# GD32E51x_HD register map
File version: 1.0
CPU: CM33 r0p4, little endian, MPU, FPU, 4 interrupt priority bits
Registers are 32-bit, read-write, reset 0x0 unless marked. A register's access mark holds for its fields unless they carry their own. Offsets are from the block's base; [hi:lo] are bit positions; {n}, {i} and the like mark numbered series.

## BKP — Backup registers
Base 0x40006C00
{0x4+4i} DATA{i} 16-bit (i=0..9) — Backup data register {i}
  [15:0] DATA — Backup data
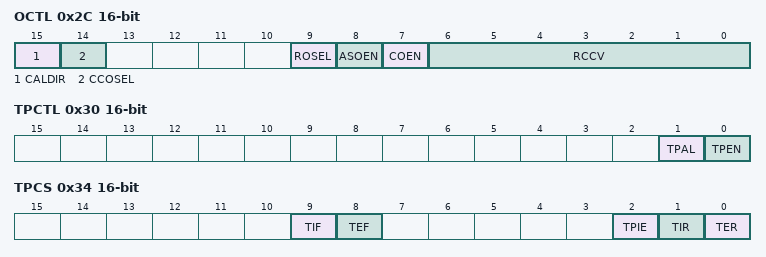
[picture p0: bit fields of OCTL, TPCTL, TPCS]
0x2C OCTL 16-bit — RTC signal output control register
  [15] CALDIR — RTC clock calibration direction
  [14] CCOSEL — RTC clock output selection
  [9] ROSEL — RTC output selection
  [8] ASOEN — RTC alarm or second signal output enable
  [7] COEN — RTC clock calibration output enable
  [6:0] RCCV — RTC clock calibration value
0x30 TPCTL 16-bit — Tamper pin control register
  [1] TPAL — TAMPER pin active level
  [0] TPEN — TAMPER detection enable
0x34 TPCS 16-bit — Tamper control and status register
  [9] TIF — Tamper interrupt flag
  [8] TEF — Tamper event flag
  [2] TPIE — Tamper interrupt enable
  [1] TIR — Tamper interrupt reset
  [0] TER — Tamper event reset
{0x18+4i} DATA{i} 16-bit (i=10..41) — Backup data register {i}
  [15:0] DATA — Backup data

## CMP — Comparator
Base 0x40017C00
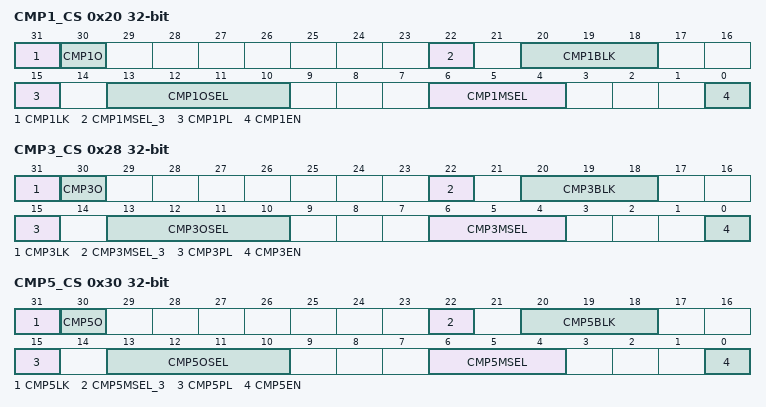
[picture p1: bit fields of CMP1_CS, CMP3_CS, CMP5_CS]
0x20 CMP1_CS access per field — CMP1 control and status register
  [31] CMP1LK rw — Comparator 1 lock
  [30] CMP1O ro — CMP1 output
  [22] CMP1MSEL_3 rw — CMP1_IM input selection
  [20:18] CMP1BLK rw — CMP1 output blanking source
  [15] CMP1PL rw — Polarity of comparator 1 output
  [13:10] CMP1OSEL rw — Comparator 1 output selection
  [6:4] CMP1MSEL rw — Comparator 1 input selection
  [0] CMP1EN rw — Comparator 1 enable
0x28 CMP3_CS access per field — CMP3 control and status register
  [31] CMP3LK rw — Comparator 3 lock
  [30] CMP3O ro — CMP3 output
  [22] CMP3MSEL_3 rw — CMP3_IM input selection
  [20:18] CMP3BLK rw — CMP3 output blanking source
  [15] CMP3PL rw — Polarity of comparator 3 output
  [13:10] CMP3OSEL rw — Comparator 3 output selection
  [6:4] CMP3MSEL rw — Comparator 3 input selection
  [0] CMP3EN rw — Comparator 3 enable
0x30 CMP5_CS access per field — CMP5 control and status register
  [31] CMP5LK rw — Comparator 5 lock
  [30] CMP5O ro — CMP5 output
  [22] CMP5MSEL_3 rw — CMP5_IM input selection
  [20:18] CMP5BLK rw — CMP5 output blanking source
  [15] CMP5PL rw — Polarity of comparator 5 output
  [13:10] CMP5OSEL rw — Comparator 5 output selection
  [6:4] CMP5MSEL rw — Comparator 5 input selection
  [0] CMP5EN rw — Comparator 5 enable

## CRC — cyclic redundancy check calculation unit
Base 0x40023000
0x00 DATA reset 0xFFFFFFFF
  [31:0] DATA — CRC calculation result bits
0x04 FDATA — Free data register
  [7:0] FDATA — Free Data Register bits
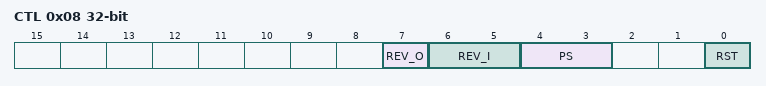
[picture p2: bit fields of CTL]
0x08 CTL — Control register
  [7] REV_O — Reverse output data value in bit order
  [6:5] REV_I — Reverse type for input data
  [4:3] PS — Size of polynomial
  [0] RST — reset bit
0x10 IDATA reset 0xFFFFFFFF — Initialization data register
  [31:0] IDATA — Configurable initial CRC data value
0x14 POLY reset 0x4C11DB7 — Polynomial register
  [31:0] POLY — User configurable polynomial value

## CTC — Clock trim controller
Base 0x4000C800
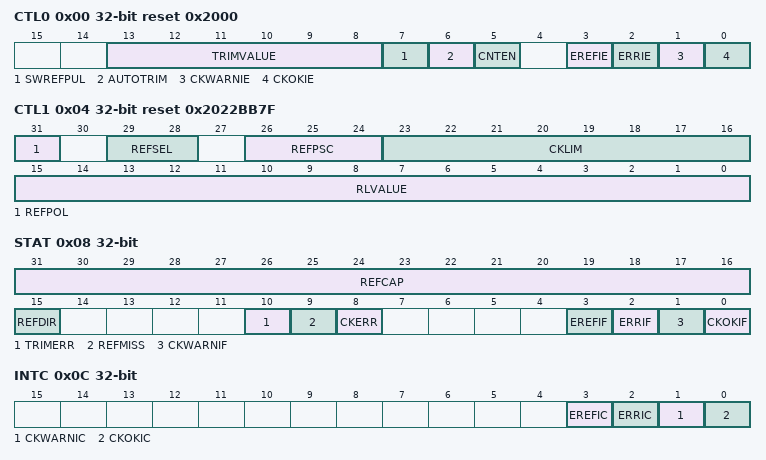
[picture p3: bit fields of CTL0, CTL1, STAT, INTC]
0x00 CTL0 reset 0x2000 — Control register 0
  [13:8] TRIMVALUE — IRC48M trim value
  [7] SWREFPUL — Software reference source sync pulse
  [6] AUTOTRIM — Hardware automatically trim mode
  [5] CNTEN — CTC counter enable
  [3] EREFIE — EREFIF interrupt enable
  [2] ERRIE — Error interrupt enable
  [1] CKWARNIE — Clock trim warning interrupt enable
  [0] CKOKIE — Clock trim ok interrupt enable
0x04 CTL1 reset 0x2022BB7F — Control register 1
  [31] REFPOL — Reference signal source polarity
  [29:28] REFSEL — Reference signal source selection
  [26:24] REFPSC — Reference signal source prescaler
  [23:16] CKLIM — Clock trim base limit value
  [15:0] RLVALUE — CTC counter reload value
0x08 STAT ro — Status register
  [31:16] REFCAP — CTC counter capture when reference sync pulse
  [15] REFDIR — CTC trim counter direction when reference sync pulse
  [10] TRIMERR — Trim value error bit
  [9] REFMISS — Reference sync pulse miss
  [8] CKERR — Clock trim error bit
  [3] EREFIF — Expect reference interrupt flag
  [2] ERRIF — Error interrupt flag
  [1] CKWARNIF — Clock trim warning interrupt flag
  [0] CKOKIF — Clock trim OK interrupt flag
0x0C INTC wo — Interrupt clear register
  [3] EREFIC — EREFIF interrupt clear bit
  [2] ERRIC — ERRIF interrupt clear bit
  [1] CKWARNIC — CKWARNIF interrupt clear bit
  [0] CKOKIC — CKOKIF interrupt clear bit
